VERSION ""

NS_ :

BS_:

BU_: BRIDGE MASTER GEO MOTOR SENSOR

BO_ 768 GEO_HEARTBEAT: 1 GEO
 SG_ GEO_HEARTBEAT_cmd : 0|8@1+ (1,0) [0|0] "" MASTER

BO_ 256 SENSOR_HEARTBEAT: 1 SENSOR
 SG_ SENSOR_HEARTBEAT_cmd : 0|8@1+ (1,0) [0|0] "" MASTER

BO_ 1024 BRIDGE_HEARTBEAT: 1 BRIDGE
 SG_ BRIDGE_HEARTBEAT_cmd : 0|8@1+ (1,0) [0|0] "" MASTER

BO_ 512 MOTOR_HEARTBEAT: 1 MOTOR
 SG_ MOTOR_HEARTBEAT_cmd : 0|8@1+ (1,0) [0|0] "" MASTER

BO_ 0 MASTER_HEARTBEAT: 1 MASTER
 SG_ MASTER_HEARTBEAT_cmd : 0|8@1+ (1,0) [0|0] "" MOTOR

BO_ 2 MASTER_DEBUG: 4 MASTER
 SG_ MASTER_DEBUG_navigation_state_enum : 0|8@1+ (1,0) [0|0] "" MOTOR
 SG_ MASTER_DEBUG_navigation_go : 8|1@1+ (1,0) [0|0] "" MOTOR

BO_ 770 GEO_COORDINATE_DATA: 8 GEO
 SG_ GEO_DATA_Latitude : 0|32@1+ (0.00000001,0) [0|0] "" MASTER,BRIDGE
 SG_ GEO_DATA_Longitude : 32|32@1+ (0.0000001,-150) [0|0] "" MASTER,BRIDGE

BO_ 771 GEO_DEBUG_DATA: 8 GEO
 SG_ GEO_COMPASS_Calibration : 0|8@1+ (1,0) [0|0] "" MASTER,BRIDGE
 SG_ GEO_COMPASS_Heading : 8|32@1+ (0.1,0) [0|0] "" MASTER,BRIDGE

BO_ 769 GEO_DATA: 8 GEO
 SG_ GEO_DATA_Distance : 0|32@1+ (0.01,0) [0|0] "" MASTER,BRIDGE
 SG_ GEO_DATA_Angle : 32|32@1+ (0.1,-180) [0|0] "" MASTER,BRIDGE

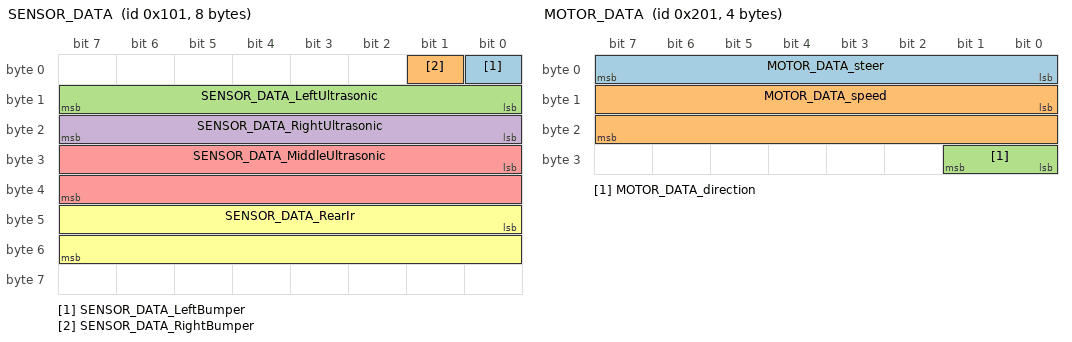
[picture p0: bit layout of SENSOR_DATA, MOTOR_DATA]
BO_ 257 SENSOR_DATA: 8 SENSOR
 SG_ SENSOR_DATA_LeftBumper : 0|1@1+ (1,0) [0|0] "" MASTER
 SG_ SENSOR_DATA_RightBumper : 1|1@1+ (1,0) [0|0] "" MASTER
 SG_ SENSOR_DATA_LeftUltrasonic : 8|8@1+ (1,0) [0|0] "" MASTER
 SG_ SENSOR_DATA_RightUltrasonic : 16|8@1+ (1,0) [0|0] "" MASTER
 SG_ SENSOR_DATA_MiddleUltrasonic : 24|16@1+ (1,0) [0|0] "" MASTER
 SG_ SENSOR_DATA_RearIr : 40|16@1+ (1,0) [0|0] "" MASTER

BO_ 1025 BRIDGE_DATA_CMD: 1 BRIDGE
 SG_ BRIDGE_DATA_CMD_start_stop : 0|1@1+ (1,0) [0|1] "" MASTER

BO_ 1026 BRIDGE_CHECKPOINT: 8 BRIDGE
 SG_ BRIDGE_DATA_Latitude : 0|32@1+ (0.00000001,0) [0|0] "" MASTER,GEO
 SG_ BRIDGE_DATA_Longitude : 32|32@1+ (0.0000001,-150) [0|0] "" MASTER,GEO

BO_ 513 MOTOR_DATA: 4 MOTOR
 SG_ MOTOR_DATA_steer : 0|8@1- (1,0) [0|0] "" MASTER,BRIDGE
 SG_ MOTOR_DATA_speed : 8|16@1+ (0.1,0) [0|0] "MPS" MASTER,BRIDGE
 SG_ MOTOR_DATA_direction : 24|2@1+ (1,0) [0|0] "" MASTER,BRIDGE

BO_ 514 MOTOR_DEBUG: 8 MOTOR
 SG_ MOTOR_DEBUG_mux M : 0|8@1+ (1,0) [0|0] "" MASTER,BRIDGE,DEBUG
 SG_ MOTOR_DEBUG_rpm_partial m0 : 8|8@1- (1,0) [0|0] "rpm" MASTER,BRIDGE,DEBUG
 SG_ MOTOR_DEBUG_rpm_actual m0 : 16|32@1- (0.01,0) [0|0] "rpm" MASTER,BRIDGE,DEBUG
 SG_ MOTOR_DEBUG_pi_error m1 : 8|32@1- (0.01,0) [0|0] "mps" MASTER,BRIDGE,DEBUG
 SG_ MOTOR_DEBUG_large_error_cnt m1 : 40|8@1+ (1,0) [0|0] "" MASTER,BRIDGE,DEBUG
 SG_ MOTOR_DEBUG_prop_cmd m2 : 8|32@1- (0.01,0) [0|0] "" MASTER,BRIDGE,DEBUG
 SG_ MOTOR_DEBUG_int_cmd m3 : 8|32@1- (0.01,0) [0|0] "" MASTER,BRIDGE,DEBUG
 SG_ MOTOR_DEBUG_int_cmd_old m4 : 8|32@1- (0.01,0) [0|0] "" MASTER,BRIDGE,DEBUG
 SG_ MOTOR_DEBUG_output m5 : 8|32@1- (0.01,0) [0|0] "percent" MASTER,BRIDGE,DEBUG
 SG_ MOTOR_DEBUG_pwm_act m6 : 8|32@1- (0.01,0) [0|0] "pwm pulse width" MASTER,BRIDGE,DEBUG

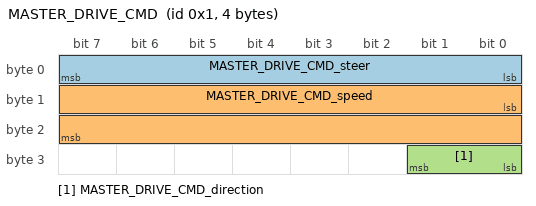
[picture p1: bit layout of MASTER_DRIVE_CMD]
BO_ 1 MASTER_DRIVE_CMD: 4 MASTER
 SG_ MASTER_DRIVE_CMD_steer : 0|8@1- (1,0) [0|0] "" MOTOR
 SG_ MASTER_DRIVE_CMD_speed : 8|16@1+ (0.1,0) [0|0] "MPS" MOTOR
 SG_ MASTER_DRIVE_CMD_direction : 24|2@1+ (1,0) [0|0] "" MOTOR

BA_DEF_ "BusType" STRING ;

BA_DEF_DEF_ "BusType" "CAN";
